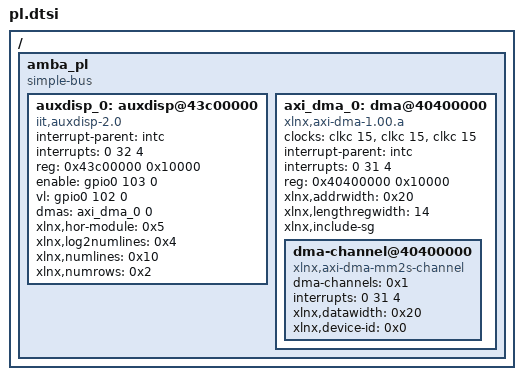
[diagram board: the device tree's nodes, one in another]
/*
 * CAUTION: This file is automatically generated by Xilinx.
 * Version:  
 * Today is: Mon Apr 23 14:16:28 2018
 */


/ {
	amba_pl: amba_pl {
		#address-cells = <1>;
		#size-cells = <1>;
		compatible = "simple-bus";
		ranges ;
		auxdisp_0: auxdisp@43c00000 {
			compatible = "iit,auxdisp-2.0";
			interrupt-names = "interrupt";
			interrupt-parent = <&intc>;
			interrupts = <0 32 4>;
			reg = <0x43c00000 0x10000>;
			/* 103 = 54(offset default for gpio) + 49 */
			enable = <&gpio0 103 0>;
			/* 102 = 54(offset default for gpio) + 48 */
			vl = <&gpio0 102 0>;
			dmas = <&axi_dma_0 0>;
			dma-names = "tx";
            xlnx,hor-module = <0x5>;
			xlnx,log2numlines = <0x4>;
			xlnx,numlines = <0x10>;
			xlnx,numrows = <0x2>;
		};
		axi_dma_0: dma@40400000 {
			#dma-cells = <1>;
			clock-names = "s_axi_lite_aclk", "m_axi_sg_aclk", "m_axi_mm2s_aclk";
			clocks = <&clkc 15>, <&clkc 15>, <&clkc 15>;
			compatible = "xlnx,axi-dma-1.00.a";
			interrupt-names = "mm2s_introut";
			interrupt-parent = <&intc>;
			interrupts = <0 31 4>;
			reg = <0x40400000 0x10000>;
			xlnx,addrwidth = <0x20>;
			xlnx,lengthregwidth=<14>;
			xlnx,include-sg ;
			dma-channel@40400000 {
				compatible = "xlnx,axi-dma-mm2s-channel";
				dma-channels = <0x1>;
				interrupts = <0 31 4>;
				xlnx,datawidth = <0x20>;
				xlnx,device-id = <0x0>;
			};
		};
	};
};
